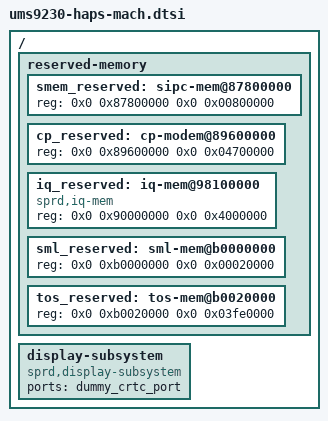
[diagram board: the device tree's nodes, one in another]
/*
 * Spreadtrum Qogirl6 board common DTS file
 *
 * Copyright (C) 2020, Spreadtrum Communications Inc.
 *
 * This file is licensed under a dual GPLv2 or X11 license.
 */


/{
	reserved-memory {
		#address-cells = <2>;
		#size-cells = <2>;
		ranges;

		smem_reserved: sipc-mem@87800000{
			reg = <0x0 0x87800000 0x0 0x00800000>;
		};

		cp_reserved: cp-modem@89600000 {
			reg = <0x0 0x89600000 0x0 0x04700000>;
		};

		/* Only used for iq, will be removed in normal mode by uboot */
		iq_reserved: iq-mem@98100000{
			compatible = "sprd,iq-mem";
			reg = <0x0 0x90000000 0x0 0x4000000>;
		};

		/* must be 64M aligned */
		sml_reserved: sml-mem@b0000000 {
			reg = <0x0 0xb0000000 0x0 0x00020000>;
		};

		tos_reserved: tos-mem@b0020000 {
			reg = <0x0 0xb0020000 0x0 0x03fe0000>;
		};

	};

	display-subsystem {
		compatible = "sprd,display-subsystem";
		ports = <&dummy_crtc_port>;
	};
};
